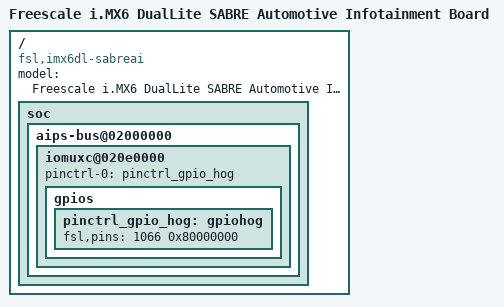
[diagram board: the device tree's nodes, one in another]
/*
 * Copyright 2013 Freescale Semiconductor, Inc.
 *
 * This program is free software; you can redistribute it and/or modify
 * it under the terms of the GNU General Public License version 2 as
 * published by the Free Software Foundation.
 *
 */

/dts-v1/;
/include/ "imx6dl.dtsi"
/include/ "imx6qdl-sabreai.dtsi"

/ {
	model = "Freescale i.MX6 DualLite SABRE Automotive Infotainment Board";
	compatible = "fsl,imx6dl-sabreai", "fsl,imx6dl";

	soc {
		aips-bus@02000000 { /* AIPS1 */
			iomuxc@020e0000 {
				pinctrl-names = "default";
				pinctrl-0 = <&pinctrl_gpio_hog>;

				gpios {
					pinctrl_gpio_hog: gpiohog {
						fsl,pins = <
							/*RGMII Phy Interrupt */
							1066 0x80000000 /* MX6SDL_PAD_GPIO_19__GPIO_4_5 */
						>;
					};
				};
			};
		};
	};
};
